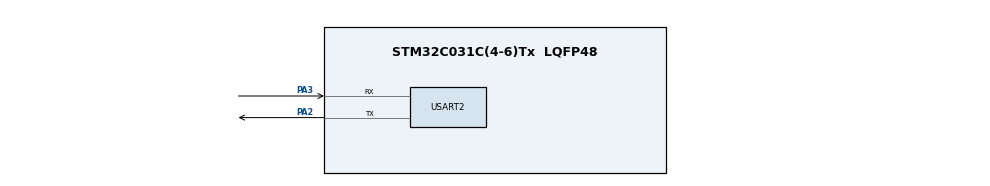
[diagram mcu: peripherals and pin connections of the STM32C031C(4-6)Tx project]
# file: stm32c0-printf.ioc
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Mcu.Family=STM32C0
Mcu.Name=STM32C031C(4-6)Tx
Mcu.Package=LQFP48
PA2.Mode=Asynchronous
PA2.Signal=USART2_TX
PA3.Mode=Asynchronous
PA3.Signal=USART2_RX
ProjectManager.HeapSize=0x200
ProjectManager.StackSize=0x400
ProjectManager.TargetToolchain=STM32CubeIDE
RCC.ADCFreq_Value=48000000
RCC.AHBFreq_Value=48000000
RCC.CortexFreq_Value=48000000
RCC.EXTERNAL_CLOCK_VALUE=12288000
RCC.HCLKFreq_Value=48000000
RCC.HSE_VALUE=8000000
RCC.HSISYSCLKDivider=RCC_HSI_DIV1
RCC.HSI_VALUE=48000000
RCC.LSE_VALUE=32768
RCC.SYSCLKFreq_VALUE=48000000
USART2.VirtualMode-Asynchronous=VM_ASYNC
board=custom

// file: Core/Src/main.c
/* USER CODE BEGIN Header */
/**
  ******************************************************************************
  * @file           : main.c
  * @brief          : Main program body
  ******************************************************************************
  * @attention
  *
  * Copyright (c) 2024 STMicroelectronics.
  * All rights reserved.
  *
  * This software is licensed under terms that can be found in the LICENSE file
  * in the root directory of this software component.
  * If no LICENSE file comes with this software, it is provided AS-IS.
  *
  ******************************************************************************
  */
/* USER CODE END Header */
#include "main.h"

UART_HandleTypeDef huart2;

void SystemClock_Config(void);
static void MX_GPIO_Init(void);
static void MX_USART2_UART_Init(void);
/* USER CODE BEGIN PFP */
#define PUTCHAR_PROTOTYPE int __io_putchar(int ch)
/* USER CODE END PFP */

int main(void)
{

  /* MCU Configuration--------------------------------------------------------*/

  /* Reset of all peripherals, Initializes the Flash interface and the Systick. */
  HAL_Init();

  /* Configure the system clock */
  SystemClock_Config();

  /* Initialize all configured peripherals */
  MX_GPIO_Init();
  MX_USART2_UART_Init();

  /* Infinite loop */
  /* USER CODE BEGIN WHILE */
  while (1)
  {
	  printf("** Hello World, Efraim! ** \n\r");
	  HAL_Delay(1000);
    /* USER CODE END WHILE */

  }
}

void SystemClock_Config(void)
{
  RCC_OscInitTypeDef RCC_OscInitStruct = {0};
  RCC_ClkInitTypeDef RCC_ClkInitStruct = {0};

  /** Initializes the RCC Oscillators according to the specified parameters
  * in the RCC_OscInitTypeDef structure.
  */
  RCC_OscInitStruct.OscillatorType = RCC_OSCILLATORTYPE_HSI;
  RCC_OscInitStruct.HSIState = RCC_HSI_ON;
  RCC_OscInitStruct.HSIDiv = RCC_HSI_DIV1;
  RCC_OscInitStruct.HSICalibrationValue = RCC_HSICALIBRATION_DEFAULT;
  if (HAL_RCC_OscConfig(&RCC_OscInitStruct) != HAL_OK)
  {
    Error_Handler();
  }

  /** Initializes the CPU, AHB and APB buses clocks
  */
  RCC_ClkInitStruct.ClockType = RCC_CLOCKTYPE_HCLK|RCC_CLOCKTYPE_SYSCLK
                              |RCC_CLOCKTYPE_PCLK1;
  RCC_ClkInitStruct.SYSCLKSource = RCC_SYSCLKSOURCE_HSI;
  RCC_ClkInitStruct.SYSCLKDivider = RCC_SYSCLK_DIV1;
  RCC_ClkInitStruct.AHBCLKDivider = RCC_HCLK_DIV1;
  RCC_ClkInitStruct.APB1CLKDivider = RCC_APB1_DIV1;

  if (HAL_RCC_ClockConfig(&RCC_ClkInitStruct, FLASH_LATENCY_1) != HAL_OK)
  {
    Error_Handler();
  }
}

static void MX_USART2_UART_Init(void)
{

  huart2.Instance = USART2;
  huart2.Init.BaudRate = 115200;
  huart2.Init.WordLength = UART_WORDLENGTH_8B;
  huart2.Init.StopBits = UART_STOPBITS_1;
  huart2.Init.Parity = UART_PARITY_NONE;
  huart2.Init.Mode = UART_MODE_TX_RX;
  huart2.Init.HwFlowCtl = UART_HWCONTROL_NONE;
  huart2.Init.OverSampling = UART_OVERSAMPLING_16;
  huart2.Init.OneBitSampling = UART_ONE_BIT_SAMPLE_DISABLE;
  huart2.Init.ClockPrescaler = UART_PRESCALER_DIV1;
  huart2.AdvancedInit.AdvFeatureInit = UART_ADVFEATURE_NO_INIT;
  if (HAL_UART_Init(&huart2) != HAL_OK)
  {
    Error_Handler();
  }

}

static void MX_GPIO_Init(void)
{

  /* GPIO Ports Clock Enable */
  __HAL_RCC_GPIOA_CLK_ENABLE();

}

/* USER CODE BEGIN 4 */
PUTCHAR_PROTOTYPE
{
	HAL_UART_Transmit(&huart2, (uint8_t *)&ch, 1, 0xFFFF);
	return ch;
}
/* USER CODE END 4 */

void Error_Handler(void)
{
  __disable_irq();
  while (1)
  {
  }
}
